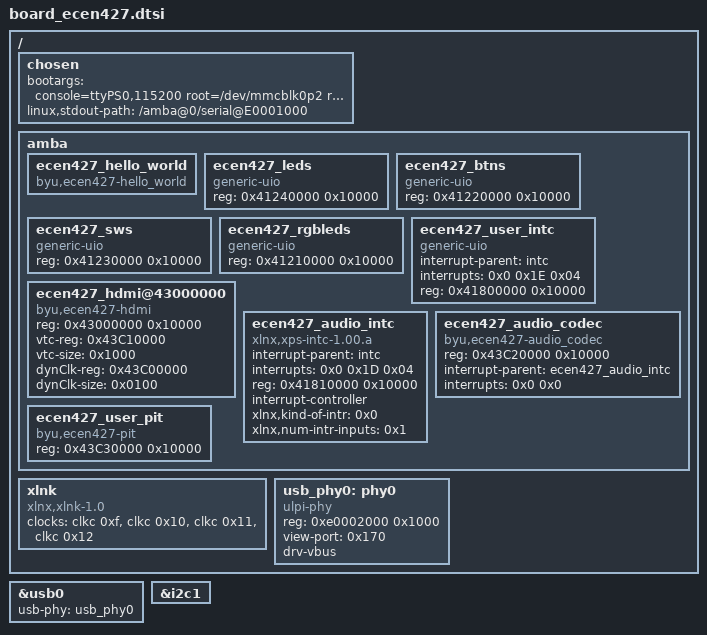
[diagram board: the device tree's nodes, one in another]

/ {
	chosen {
		bootargs = "console=ttyPS0,115200 root=/dev/mmcblk0p2 rw earlyprintk rootfstype=ext4 rootwait devtmpfs.mount=1 uio_pdrv_genirq.of_id=\"generic-uio\"";
		linux,stdout-path = "/amba@0/serial@E0001000";
	};

	amba {

		ecen427_hello_world {
			compatible = "byu,ecen427-hello_world";
		};

/********************************* UIO Start **********************************/
		ecen427_leds {
			compatible = "generic-uio";
			reg = <0x41240000 0x10000>;
		};

		ecen427_btns {
			compatible = "generic-uio";
			reg = <0x41220000 0x10000>;
		};

		ecen427_sws {
			compatible = "generic-uio";
			reg = <0x41230000 0x10000>;
		};

		ecen427_rgbleds {
			compatible = "generic-uio";
			reg = <0x41210000 0x10000>;
		};

		ecen427_user_intc {
			compatible = "generic-uio";
			interrupt-parent = <&intc>;
			interrupts = <0x0 0x1E 0x04>;
			reg = <0x41800000 0x10000>;
		};

/******************************** Video Start *********************************/
		ecen427_hdmi@43000000 {
			compatible = "byu,ecen427-hdmi";
			reg = <0x43000000 0x10000>;
			vtc-reg = <0x43C10000>;
			vtc-size = <0x1000>;
			dynClk-reg = <0x43C00000>;
			dynClk-size = <0x0100>;
		};

/******************************** Audio Start *********************************/
		ecen427_audio_intc: ecen427_audio_intc {
			compatible = "xlnx,xps-intc-1.00.a";
			interrupt-parent = <&intc>;
			interrupts = <0x0 0x1D 0x04>;
			reg = <0x41810000 0x10000>;
			interrupt-controller;
			#interrupt-cells = <1>;
			xlnx,kind-of-intr = <0x0>;
			xlnx,num-intr-inputs = <0x1>;
		};

		ecen427_audio_codec {
			compatible = "byu,ecen427-audio_codec";
			reg = <0x43C20000 0x10000>;
			interrupt-parent = <&ecen427_audio_intc>;
			interrupts = <0x0 0x0>;
		};

/******************************** Pit Start *********************************/
		ecen427_user_pit {
			compatible = "byu,ecen427-pit";
			reg = <0x43C30000 0x10000>;
		};

	};


	xlnk {
		compatible = "xlnx,xlnk-1.0";
		clock-names = "xclk0", "xclk1", "xclk2", "xclk3";
		clocks = <&clkc 0xf &clkc 0x10 &clkc 0x11 &clkc 0x12>;
	};
	usb_phy0: phy0 {
		compatible = "ulpi-phy";
		#phy-cells = <0>;
 		reg = <0xe0002000 0x1000>;
		view-port = <0x170>;
		drv-vbus;
	};

};

&usb0 {
	usb-phy = <&usb_phy0>;
};

&i2c1 {
	status = "okay";
};
